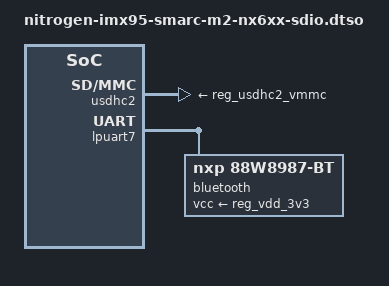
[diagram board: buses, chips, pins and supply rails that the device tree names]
// SPDX-License-Identifier: (GPL-2.0+ OR MIT)
/*
 * SDIO NX6xx module
 *
 * Copyright (C) 2024 Ezurio LLC
 */

/dts-v1/;
/plugin/;

// M.2 SDIO is disabled by default on SMARC carrier board
// requires switching 0 Ohm resistors to enable	

&reg_usdhc2_vmmc {
	startup-delay-us = <20000>;
	off-on-delay-us = <100>;
};

&usdhc2 {
	vmmc-supply = <&reg_usdhc2_vmmc>;
};

&lpuart7 {
	status = "okay";

	bluetooth {
		compatible = "nxp,88w8987-bt";
		fw-init-baudrate = <3000000>;
		vcc-supply = <&reg_vdd_3v3>;
	};
};
